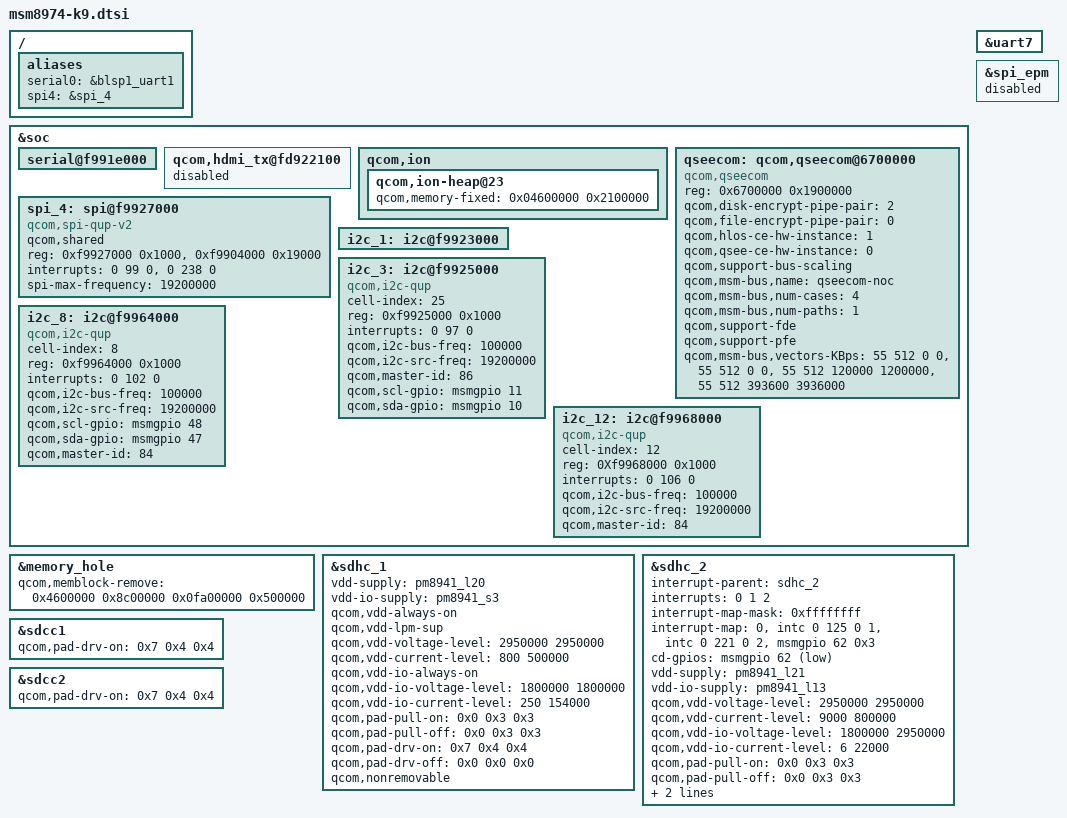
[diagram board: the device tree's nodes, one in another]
/* Copyright (c) 2012-2014, The Linux Foundation. All rights reserved.
 *
 * This program is free software; you can redistribute it and/or modify
 * it under the terms of the GNU General Public License version 2 and
 * only version 2 as published by the Free Software Foundation.
 *
 * This program is distributed in the hope that it will be useful,
 * but WITHOUT ANY WARRANTY; without even the implied warranty of
 * MERCHANTABILITY or FITNESS FOR A PARTICULAR PURPOSE.  See the
 * GNU General Public License for more details.
 */

/include/ "msm8974-k9-audio.dtsi"
/include/ "msm8974-k9-camera.dtsi"
/include/ "msm8974-k9-camera-sensor.dtsi"
/include/ "msm8974-k9-keys.dtsi"
/include/ "msm8974-k9-leds.dtsi"
/include/ "msm8974-k9-mdss.dtsi"
/include/ "msm8974-k9-misc.dtsi"
/include/ "msm8974-k9-panels.dtsi"
/include/ "msm8974-k9-pm8941.dtsi"
/include/ "msm8974-k9-regulator.dtsi"
/include/ "msm8974-k9-sensors.dtsi"
/include/ "msm8974-k9-touchpanel.dtsi"
/include/ "msm8974-k9-usb.dtsi"

/ {
	aliases {
		serial0 = &blsp1_uart1;
		spi4 = &spi_4;
	};
};

&soc {
	serial@f991e000 {
		status = "ok";
	};

	qcom,hdmi_tx@fd922100 {
		status = "disabled";
	};

	qcom,ion {
		qcom,ion-heap@23 { 
			qcom,memory-fixed = <0x04600000 0x2100000>;
		};
	};

	/delete-node/ qcom,qseecom@7b00000;
	qseecom: qcom,qseecom@6700000 {
		compatible = "qcom,qseecom";
		reg = <0x6700000 0x1900000>;
		reg-names = "secapp-region";
		qcom,disk-encrypt-pipe-pair = <2>;
		qcom,file-encrypt-pipe-pair = <0>;
		qcom,hlos-ce-hw-instance = <1>;
		qcom,qsee-ce-hw-instance = <0>;
		qcom,support-bus-scaling;
		qcom,msm-bus,name = "qseecom-noc";
		qcom,msm-bus,num-cases = <4>;
		qcom,msm-bus,num-paths = <1>;
		qcom,support-fde;
		qcom,support-pfe;
		qcom,msm-bus,vectors-KBps =
			<55 512 0 0>,
			<55 512 0 0>,
			<55 512 120000 1200000>,
			<55 512 393600 3936000>;
	};

	spi_4: spi@f9927000 { /* BLSP1 QUP5 */
		compatible = "qcom,spi-qup-v2";
		qcom,shared;
		#address-cells = <1>;
		#size-cells = <0>;
		reg-names = "spi_physical", "spi_bam_physical";
		reg = <0xf9927000 0x1000>,
				<0xf9904000 0x19000>;
		interrupt-names = "spi_irq", "spi_bam_irq";
		interrupts = <0 99 0>, <0 238 0>;
		spi-max-frequency = <19200000>;
	};

	/* Enable i2c_1 */
	i2c_1: i2c@f9923000 {
		status = "okay";
	};

	i2c_3: i2c@f9925000 {
		cell-index = <25>;
		compatible = "qcom,i2c-qup";
		reg = <0xf9925000 0x1000>;
		#address-cells = <1>;
		#size-cells = <0>;
		reg-names = "qup_phys_addr";
		interrupts = <0 97 0>;
		interrupt-names = "qup_err_intr";
		qcom,i2c-bus-freq = <100000>;
		qcom,i2c-src-freq = <19200000>;
		qcom,master-id = <86>;
		qcom,scl-gpio = <&msmgpio 11 0>;
		qcom,sda-gpio = <&msmgpio 10 0>;
	};

	i2c_8: i2c@f9964000 {// BLSP#8
		cell-index = <8>;
		compatible = "qcom,i2c-qup";
		reg = <0xf9964000 0x1000>;
		#address-cells = <1>;
		#size-cells = <0>;
		reg-names = "qup_phys_addr";
		interrupts = <0 102 0>;
		interrupt-names = "qup_err_intr";
		qcom,i2c-bus-freq = <100000>;
		qcom,i2c-src-freq = <19200000>;
		qcom,scl-gpio = <&msmgpio 48 0>;
		qcom,sda-gpio = <&msmgpio 47 0>;
		qcom,master-id = <84>;
	};

	i2c_12: i2c@f9968000 { /* BLSP#12 */
		cell-index = <12>;
		compatible = "qcom,i2c-qup";
		reg = <0Xf9968000 0x1000>;
		#address-cells = <1>;
		#size-cells = <0>;
		reg-names = "qup_phys_addr";
		interrupts = <0 106 0>;
		interrupt-names = "qup_err_intr";
		qcom,i2c-bus-freq = <100000>;
		qcom,i2c-src-freq = <19200000>;
		qcom,master-id = <84>;
	};
};

&memory_hole {
	qcom,memblock-remove = <0x4600000 0x8c00000
		0x0fa00000 0x500000>; /* Address and size of the hole */
};

&sdhc_1 {
	vdd-supply = <&pm8941_l20>;
	vdd-io-supply = <&pm8941_s3>;

	qcom,vdd-always-on;
	qcom,vdd-lpm-sup;
	qcom,vdd-voltage-level = <2950000 2950000>;
	qcom,vdd-current-level = <800 500000>;

	qcom,vdd-io-always-on;
	qcom,vdd-io-voltage-level = <1800000 1800000>;
	qcom,vdd-io-current-level = <250 154000>;

	qcom,pad-pull-on = <0x0 0x3 0x3>; /* no-pull, pull-up, pull-up */
	qcom,pad-pull-off = <0x0 0x3 0x3>; /* no-pull, pull-up, pull-up */
	qcom,pad-drv-on = <0x4 0x4 0x4>; /* 10mA, 10mA, 10mA */
	qcom,pad-drv-off = <0x0 0x0 0x0>; /* 2mA, 2mA, 2mA */

	qcom,nonremovable;
	status = "ok";
};

&sdhc_2 {
	#address-cells = <0>;
	interrupt-parent = <&sdhc_2>;
	interrupts = <0 1 2>;
	#interrupt-cells = <1>;
	interrupt-map-mask = <0xffffffff>;
	interrupt-map = <0 &intc 0 125 0
		1 &intc 0 221 0
		2 &msmgpio 62 0x3>;
	interrupt-names = "hc_irq", "pwr_irq", "status_irq";
	cd-gpios = <&msmgpio 62 0x1>;

	vdd-supply = <&pm8941_l21>;
	vdd-io-supply = <&pm8941_l13>;

	qcom,vdd-voltage-level = <2950000 2950000>;
	qcom,vdd-current-level = <9000 800000>;

	qcom,vdd-io-voltage-level = <1800000 2950000>;
	qcom,vdd-io-current-level = <6 22000>;

	qcom,pad-pull-on = <0x0 0x3 0x3>; /* no-pull, pull-up, pull-up */
	qcom,pad-pull-off = <0x0 0x3 0x3>; /* no-pull, pull-up, pull-up */
	qcom,pad-drv-on = <0x4 0x4 0x4>; /* 10mA, 10mA, 10mA */
	qcom,pad-drv-off = <0x0 0x0 0x0>; /* 2mA, 2mA, 2mA */
	status = "ok";
};

/* Drive strength recommendations for clock line from hardware team is 10 mA.
 * But since the driver has been been using the below values from the start
 * without any problems, continue to use those.
 */
&sdcc1 {
	qcom,pad-drv-on = <0x7 0x4 0x4>; /* 16mA, 10mA, 10mA */
};

&sdcc2 {
	qcom,pad-drv-on = <0x7 0x4 0x4>; /* 16mA, 10mA, 10mA */
};

&sdhc_1 {
	qcom,pad-drv-on = <0x7 0x4 0x4>; /* 16mA, 10mA, 10mA */
};

&sdhc_2 {
	qcom,pad-drv-on = <0x7 0x4 0x4>; /* 16mA, 10mA, 10mA */
};

&uart7 {
	status = "ok";
};

&spi_epm {
  status = "disabled";
};
